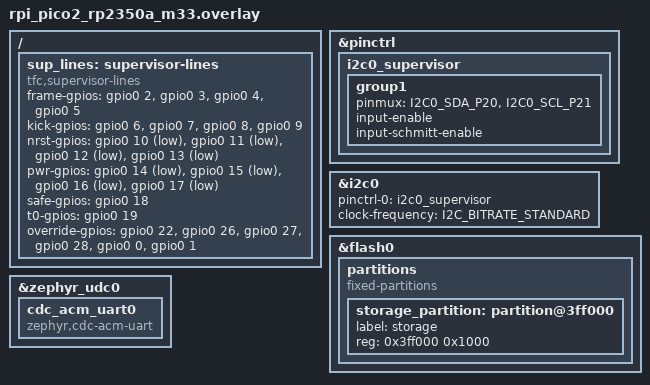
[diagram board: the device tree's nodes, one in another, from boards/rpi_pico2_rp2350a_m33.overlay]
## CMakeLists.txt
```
cmake_minimum_required(VERSION 3.20.0)
find_package(Zephyr REQUIRED HINTS $ENV{ZEPHYR_BASE})
project(tfc_supervisor LANGUAGES C CXX)

# The supervisor shares no code with core/ (TFC-SUP-001): only its own logic, supervisor/include.
target_include_directories(app PRIVATE ${CMAKE_CURRENT_LIST_DIR}/../../supervisor/include)
target_sources(app PRIVATE src/main.cpp src/usb_init.c)
```

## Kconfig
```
# SPDX-License-Identifier: MIT
mainmenu "Supervisor (Pico 2, SUP-Lite)"

config TFC_USB_VID
	hex "USB vendor id"
	default 0x1209
	help
	  The pid.codes open vendor id, for a private bench device. Nothing here is for sale or for the field.

config TFC_USB_PID
	hex "USB product id"
	default 0x0002

config TFC_WATCHDOG_TIMEOUT_MS
	int "Hardware watchdog timeout (milliseconds)"
	default 100
	range 20 4000
	help
	  A supervisor that hangs resets itself and comes back with every output at its default and a warm start (it adopts running units and touches nothing).

config TFC_OVERRIDE_LINES_FITTED
	hex "Which hardware-override sense lines are wired (bit 0 H1 E-stop .. bit 5 H6/H7 node power-kill)"
	default 0x0
	range 0 0x3F
	help
	  The overrides' parts are ordered separately (docs/design/HARDWARE_OVERRIDE.md section 8). A line that is not wired is ignored; with none wired the feature is inert. A wired line that is engaged
	  blocks `launch` and `t0` until the operator types `override-ok`; the sense lines never change what the supervisor does to a unit (TFC-HWO-005).

source "Kconfig.zephyr"
```

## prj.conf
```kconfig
CONFIG_CPP=y
CONFIG_STD_CPP17=y
# Flight-code rules (ARCHITECTURE.md section 6): no exceptions, no RTTI, no heap.
CONFIG_CPP_EXCEPTIONS=n
CONFIG_CPP_RTTI=n
CONFIG_REQUIRES_FULL_LIBCPP=y
CONFIG_COMMON_LIBC_MALLOC=n

# The USB serial link to the PC (hardware commands in, status and events out)
CONFIG_USB_DEVICE_STACK_NEXT=y
CONFIG_USBD_CDC_ACM_CLASS=y
CONFIG_SERIAL=y
CONFIG_UART_LINE_CTRL=y
CONFIG_CDC_ACM_SERIAL_INITIALIZE_AT_BOOT=n

# The lines to the nodes, the real-time clock on I2C, the record of T-zero in flash, the watchdog
CONFIG_GPIO=y
CONFIG_I2C=y
CONFIG_FLASH=y
CONFIG_FLASH_MAP=y
CONFIG_WATCHDOG=y
CONFIG_HWINFO=y

CONFIG_LOG=y
CONFIG_USBD_LOG_LEVEL_ERR=y
CONFIG_UDC_DRIVER_LOG_LEVEL_ERR=y
CONFIG_USBD_CDC_ACM_LOG_LEVEL_OFF=y
CONFIG_MAIN_STACK_SIZE=4096
```

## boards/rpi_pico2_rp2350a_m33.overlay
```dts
/* The supervisor on a Pico 2 (docs/design/SUPERVISOR.md section 4, SUP-Lite; ADR-022).
 *
 * Pins (GP numbers): FRAME in GP2 to GP5 (A, B, C, ACT), KICK in GP6 to GP9, NRST out GP10 to GP13, power relay out GP14 to GP17 (active low, external pull-ups to 3.3 V), SAFE out GP18, T0 out GP19,
 * I2C0 to the real-time clock on GP20 (SDA) and GP21 (SCL), the six override sense inputs on GP22, GP26, GP27, GP28, GP0 and GP1 (H1 to H5 and H6/H7). All 26 pins. Every input needs an external pull-down of 8.2 kOhm or less (the RP2350 E9 erratum); the unit boards' own
 * outputs are push-pull. The NRST pins are driven open-drain by the program (an output pulled low to reset, an input otherwise), because the RP2350's GPIO has no open-drain mode.
 * The record of T-zero is kept in the last 4 KB sector of the 4 MB flash.
 */
#include <zephyr/dt-bindings/gpio/gpio.h>
#include <zephyr/dt-bindings/i2c/i2c.h>
#include <zephyr/dt-bindings/pinctrl/rpi-pico-rp2350a-pinctrl.h>

&pinctrl {
	i2c0_supervisor: i2c0_supervisor {
		group1 {
			pinmux = <I2C0_SDA_P20>, <I2C0_SCL_P21>;
			input-enable;
			input-schmitt-enable;
		};
	};
};

&i2c0 {
	pinctrl-0 = <&i2c0_supervisor>;
	pinctrl-names = "default";
	clock-frequency = <I2C_BITRATE_STANDARD>;
	status = "okay";
};

&flash0 {
	partitions {
		compatible = "fixed-partitions";
		#address-cells = <1>;
		#size-cells = <1>;

		storage_partition: partition@3ff000 {
			label = "storage";
			reg = <0x3ff000 0x1000>;
		};
	};
};

/ {
	sup_lines: supervisor-lines {
		compatible = "tfc,supervisor-lines";
		frame-gpios = <&gpio0 2 GPIO_ACTIVE_HIGH>, <&gpio0 3 GPIO_ACTIVE_HIGH>, <&gpio0 4 GPIO_ACTIVE_HIGH>, <&gpio0 5 GPIO_ACTIVE_HIGH>;
		kick-gpios = <&gpio0 6 GPIO_ACTIVE_HIGH>, <&gpio0 7 GPIO_ACTIVE_HIGH>, <&gpio0 8 GPIO_ACTIVE_HIGH>, <&gpio0 9 GPIO_ACTIVE_HIGH>;
		nrst-gpios = <&gpio0 10 GPIO_ACTIVE_LOW>, <&gpio0 11 GPIO_ACTIVE_LOW>, <&gpio0 12 GPIO_ACTIVE_LOW>, <&gpio0 13 GPIO_ACTIVE_LOW>;
		pwr-gpios = <&gpio0 14 GPIO_ACTIVE_LOW>, <&gpio0 15 GPIO_ACTIVE_LOW>, <&gpio0 16 GPIO_ACTIVE_LOW>, <&gpio0 17 GPIO_ACTIVE_LOW>;
		safe-gpios = <&gpio0 18 GPIO_ACTIVE_HIGH>;
		t0-gpios = <&gpio0 19 GPIO_ACTIVE_HIGH>;
		override-gpios = <&gpio0 22 GPIO_ACTIVE_HIGH>, <&gpio0 26 GPIO_ACTIVE_HIGH>, <&gpio0 27 GPIO_ACTIVE_HIGH>, <&gpio0 28 GPIO_ACTIVE_HIGH>, <&gpio0 0 GPIO_ACTIVE_HIGH>,
				  <&gpio0 1 GPIO_ACTIVE_HIGH>;
	};
};

/* The USB serial port to the PC: one CDC ACM function on the board's USB device controller. */
&zephyr_udc0 {
	cdc_acm_uart0 {
		compatible = "zephyr,cdc-acm-uart";
	};
};
```

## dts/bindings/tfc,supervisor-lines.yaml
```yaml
# SPDX-License-Identifier: MIT
description: The supervisor's lines to the three flight computers and the actuator node (A, B, C, ACT, in that order), and to ACT and the flight computers (SAFE, T0)
compatible: "tfc,supervisor-lines"
properties:
  frame-gpios:
    type: phandle-array
    required: true
    description: FRAME inputs, one per unit; a rising edge at the start of every frame. Each needs an external pull-down of 8.2 kOhm or less (RP2350 erratum E9)
  kick-gpios:
    type: phandle-array
    required: true
    description: KICK inputs, one per unit; a rising edge at the end of every completed frame (the watchdog line, TFC-FDIR-038)
  nrst-gpios:
    type: phandle-array
    required: true
    description: NRST outputs, one per unit, driven open-drain by hand (an output pulled low to reset, an input otherwise); active low
  pwr-gpios:
    type: phandle-array
    required: true
    description: Power relay inputs, one per unit; active low with external pull-ups so that a pin that is not driven means "powered"
  safe-gpios:
    type: phandle-array
    required: true
    description: SAFE output to ACT (high is Safe); default low
  t0-gpios:
    type: phandle-array
    required: true
    description: T0 output to every flight computer (a pulse at T-zero); default low
  override-gpios:
    type: phandle-array
    description: |
      The hardware overrides' read-only sense inputs (docs/design/HARDWARE_OVERRIDE.md, TFC-HWO-005), six of them in the order of supervisor/include/sup/overrides.hpp: H1 E-stop, H2 FORCE-SAFE, H3
      PLATFORM-LEVEL, H4 INJECTOR-DISARM, H5 SUPERVISOR-DISARM, H6/H7 any node power-kill. High means engaged. Each needs an external pull-down of 8.2 kOhm or less (RP2350 erratum E9).
      Optional; which of them exist is CONFIG_TFC_OVERRIDE_LINES_FITTED.
```

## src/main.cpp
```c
// SPDX-License-Identifier: MIT
// The supervisor on the Pico 2 (SUP-Lite, docs/design/SUPERVISOR.md; ADR-022). The board's side of sup::Supervisor (supervisor/include/sup/supervisor.hpp, tested on the host with a simulation of the
// units it watches). Every millisecond this loop
//   - reads the cumulative FRAME and KICK edge counts and the tick of the latest edge of each of the four units (the edges are counted in the GPIO interrupts),
//   - reads a command line if one has come in over USB serial (reset, cycle, hold, release, safe-now, safe-clear, launch, scrub, t0, override-ok, time, status),
//   - gives both to the logic and applies the levels it returns: NRST (driven open-drain by hand), the power relays (active low, external pull-ups), SAFE and T0,
//   - answers the command and reports what happened (a reset, a power-cycle, a unit declared DEAD, a period or phase out of limit, T-zero),
//   - feeds the hardware watchdog.
// At power-up every output is at its default before anything else can go wrong: no reset, no relay, SAFE and T0 low. The record of T-zero is kept in the last flash sector, so that after a
// reset or a power cut the mission clock is resumed from the battery-backed RTC (docs/design/MISSION_CLOCK.md). It shares no code with core/ (TFC-SUP-001). None of this has been run on a board.
//
// Include the C++ standard library BEFORE Zephyr headers: Zephyr defines an `__unused` macro that breaks a glibc header.
#include <array>
#include <cstdint>
#include <cstring>

#include "sup/rtc.hpp"
#include "sup/supervisor.hpp"

#include "usb_init.h"

#include <zephyr/device.h>
#include <zephyr/devicetree.h>
#include <zephyr/drivers/gpio.h>
#include <zephyr/drivers/i2c.h>
#include <zephyr/drivers/uart.h>
#include <zephyr/drivers/watchdog.h>
#include <zephyr/kernel.h>
#include <zephyr/storage/flash_map.h>
#include <zephyr/sys/util.h>
#include <zephyr/usb/usbd.h>

namespace {

constexpr unsigned kUnits = sup::kUnits;
const struct device* const g_uart = DEVICE_DT_GET_ONE(zephyr_cdc_acm_uart);
const struct device* const g_i2c = DEVICE_DT_GET(DT_NODELABEL(i2c0));
constexpr uint16_t kRtcAddress = 0x68;

#define LINE(prop, i) GPIO_DT_SPEC_GET_BY_IDX(DT_NODELABEL(sup_lines), prop, i)
const struct gpio_dt_spec g_frame[kUnits] = {LINE(frame_gpios, 0), LINE(frame_gpios, 1), LINE(frame_gpios, 2), LINE(frame_gpios, 3)};
const struct gpio_dt_spec g_kick[kUnits] = {LINE(kick_gpios, 0), LINE(kick_gpios, 1), LINE(kick_gpios, 2), LINE(kick_gpios, 3)};
const struct gpio_dt_spec g_nrst[kUnits] = {LINE(nrst_gpios, 0), LINE(nrst_gpios, 1), LINE(nrst_gpios, 2), LINE(nrst_gpios, 3)};
const struct gpio_dt_spec g_pwr[kUnits] = {LINE(pwr_gpios, 0), LINE(pwr_gpios, 1), LINE(pwr_gpios, 2), LINE(pwr_gpios, 3)};
const struct gpio_dt_spec g_safe = GPIO_DT_SPEC_GET(DT_NODELABEL(sup_lines), safe_gpios);
const struct gpio_dt_spec g_t0 = GPIO_DT_SPEC_GET(DT_NODELABEL(sup_lines), t0_gpios);
#if DT_NODE_HAS_PROP(DT_NODELABEL(sup_lines), override_gpios)
const struct gpio_dt_spec g_override[sup::kOverrideLines] = {LINE(override_gpios, 0), LINE(override_gpios, 1), LINE(override_gpios, 2),
                                                             LINE(override_gpios, 3), LINE(override_gpios, 4), LINE(override_gpios, 5)};
constexpr bool kHaveOverrideLines = true;
#else
constexpr bool kHaveOverrideLines = false;
#endif

// The edge counters, written in the GPIO interrupt and read with interrupts off.
struct Edges {
  uint32_t frames = 0U;
  uint64_t frame_tick = 0U;
  uint32_t kicks = 0U;
  uint64_t kick_tick = 0U;
};
Edges g_edges[kUnits];

struct EdgeCallback {
  struct gpio_callback cb;
  unsigned unit;
  bool kick;
};
EdgeCallback g_callbacks[2U * kUnits];

uint64_t now_ticks() { return k_cyc_to_us_floor64(k_cycle_get_64()); }  // 1 MHz, as sup::SupConfig::tick_hz

void on_edge(const struct device*, struct gpio_callback* cb, uint32_t) {
  EdgeCallback* e = CONTAINER_OF(cb, EdgeCallback, cb);
  const uint64_t t = now_ticks();
  if (e->kick) {
    ++g_edges[e->unit].kicks;
    g_edges[e->unit].kick_tick = t;
  } else {
    ++g_edges[e->unit].frames;
    g_edges[e->unit].frame_tick = t;
  }
}

bool watch(const struct gpio_dt_spec& pin, unsigned index, unsigned unit, bool kick) {
  if (!gpio_is_ready_dt(&pin) || gpio_pin_configure_dt(&pin, GPIO_INPUT) != 0) {
    return false;
  }
  EdgeCallback& e = g_callbacks[index];
  e.unit = unit;
  e.kick = kick;
  gpio_init_callback(&e.cb, on_edge, BIT(pin.pin));
  return gpio_add_callback(pin.port, &e.cb) == 0 && gpio_pin_interrupt_configure_dt(&pin, GPIO_INT_EDGE_RISING) == 0;
}

// NRST: an output pulled low to reset, an input (high impedance) otherwise.
void set_nrst(unsigned u, bool low) {
  static bool last[kUnits];
  static bool known[kUnits];
  if (known[u] && last[u] == low) {
    return;
  }
  known[u] = true;
  last[u] = low;
  if (low) {
    (void)gpio_pin_configure_dt(&g_nrst[u], GPIO_OUTPUT_ACTIVE);
  } else {
    (void)gpio_pin_configure_dt(&g_nrst[u], GPIO_INPUT);
  }
}

void apply(const sup::Outputs& o) {
  for (unsigned u = 0; u < kUnits; ++u) {
    set_nrst(u, o.nrst_low[u]);
    (void)gpio_pin_set_dt(&g_pwr[u], o.power_cut[u] ? 1 : 0);  // the devicetree says active low: logical 1 is the relay energised
  }
  (void)gpio_pin_set_dt(&g_safe, o.safe_line ? 1 : 0);
  (void)gpio_pin_set_dt(&g_t0, o.t0_line ? 1 : 0);
}

void say(const char* text) {
  const std::size_t n = std::strlen(text);
  std::size_t sent = 0U;
  for (int tries = 0; tries < 4 && sent < n; ++tries) {  // a short write is a lost line: the operator asks again
    sent += static_cast<std::size_t>(uart_fifo_fill(g_uart, reinterpret_cast<const uint8_t*>(text) + sent, static_cast<int>(n - sent)));
  }
}

// The real-time clock: seconds since 2000-01-01, or invalid.
sup::RtcReading read_rtc() {
  std::array<uint8_t, 7> r{};
  uint8_t reg = 0x00;
  uint8_t status = 0x80;
  if (!device_is_ready(g_i2c) || i2c_write_read(g_i2c, kRtcAddress, &reg, 1, r.data(), static_cast<uint32_t>(r.size())) != 0) {
    return sup::RtcReading{};
  }
  reg = 0x0F;
  if (i2c_write_read(g_i2c, kRtcAddress, &reg, 1, &status, 1) != 0) {
    return sup::RtcReading{};
  }
  return sup::ds3231_seconds(r, status);
}

// The record of T-zero in the last flash sector.
bool load_record(sup::MetRecord& rec) {
  const struct flash_area* fa = nullptr;
  if (flash_area_open(FIXED_PARTITION_ID(storage_partition), &fa) != 0) {
    return false;
  }
  const bool ok = flash_area_read(fa, 0, &rec, sizeof rec) == 0;
  flash_area_close(fa);
  return ok;
}

void store_record(const sup::MetRecord& rec) {
  const struct flash_area* fa = nullptr;
  if (flash_area_open(FIXED_PARTITION_ID(storage_partition), &fa) != 0) {
    return;
  }
  if (flash_area_erase(fa, 0, 4096U) == 0) {
    (void)flash_area_write(fa, 0, &rec, sizeof rec);
  }
  flash_area_close(fa);
}

void usb_message(struct usbd_context* const ctx, const struct usbd_msg* msg) {
  if (usbd_can_detect_vbus(ctx)) {
    if (msg->type == USBD_MSG_VBUS_READY) {
      (void)usbd_enable(ctx);
    } else if (msg->type == USBD_MSG_VBUS_REMOVED) {
      (void)usbd_disable(ctx);
    }
  }
}

const char* const kUnitNames[kUnits] = {"A", "B", "C", "ACT"};

}  // namespace

int main() {
  // Every output at its default first: no relay energised, NRST released, SAFE and T0 low (TFC-SUP-007).
  for (unsigned u = 0; u < kUnits; ++u) {
    if (gpio_is_ready_dt(&g_pwr[u])) {
      (void)gpio_pin_configure_dt(&g_pwr[u], GPIO_OUTPUT_INACTIVE);
    }
    if (gpio_is_ready_dt(&g_nrst[u])) {
      (void)gpio_pin_configure_dt(&g_nrst[u], GPIO_INPUT);
    }
  }
  if (gpio_is_ready_dt(&g_safe)) {
    (void)gpio_pin_configure_dt(&g_safe, GPIO_OUTPUT_INACTIVE);
  }
  if (gpio_is_ready_dt(&g_t0)) {
    (void)gpio_pin_configure_dt(&g_t0, GPIO_OUTPUT_INACTIVE);
  }
  struct usbd_context* usb = tfc_usbd_init(usb_message);
  if (usb != nullptr && !usbd_can_detect_vbus(usb)) {
    (void)usbd_enable(usb);
  }
  bool lines_ok = device_is_ready(g_uart);
  for (unsigned u = 0; u < kUnits; ++u) {
    lines_ok = watch(g_frame[u], 2U * u, u, false) && watch(g_kick[u], (2U * u) + 1U, u, true) && lines_ok;
  }
  if (!lines_ok) {
    return 1;
  }

  const struct device* const wdt = DEVICE_DT_GET(DT_ALIAS(watchdog0));
  int wdt_channel = -1;
  if (device_is_ready(wdt)) {
    wdt_timeout_cfg wcfg{};
    wcfg.flags = WDT_FLAG_RESET_SOC;
    wcfg.window.min = 0U;
    wcfg.window.max = CONFIG_TFC_WATCHDOG_TIMEOUT_MS;
    wdt_channel = wdt_install_timeout(wdt, &wcfg);
    if (wdt_channel >= 0 && wdt_setup(wdt, WDT_OPT_PAUSE_HALTED_BY_DBG) != 0) {
      wdt_channel = -1;
    }
  }

  sup::SupConfig sup_cfg;
  sup_cfg.override_fitted = kHaveOverrideLines ? static_cast<uint8_t>(CONFIG_TFC_OVERRIDE_LINES_FITTED) : 0U;
#if DT_NODE_HAS_PROP(DT_NODELABEL(sup_lines), override_gpios)
  for (unsigned i = 0; i < sup::kOverrideLines; ++i) {
    if (((sup_cfg.override_fitted >> i) & 1U) != 0U && gpio_is_ready_dt(&g_override[i])) {
      (void)gpio_pin_configure_dt(&g_override[i], GPIO_INPUT);
    }
  }
#endif
  sup::Supervisor supervisor(sup_cfg);
  if (!supervisor.config_ok()) {  // a clock that cannot make a whole frame of ticks: it does not act (every node keeps running, TFC-SUP-007) and says why
    say("supervisor: the clock configuration is invalid; it will not act\n");
    for (;;) {
      k_sleep(K_FOREVER);
    }
  }
  sup::RtcReading rtc = read_rtc();
  {
    sup::MetRecord rec;
    if (rtc.valid && load_record(rec) && supervisor.restore(rec, now_ticks(), rtc.seconds)) {
      say("T-zero record found: the mission clock is resumed from the RTC (good to a second)\n");
    }
  }
  say("supervisor up\n");

  std::array<char, 48> line{};
  std::size_t line_len = 0U;
  uint64_t next_rtc = now_ticks() + 1000000U;
  int64_t next = k_uptime_get() + 1;
  for (;;) {
    sup::Inputs in;
    const unsigned key = irq_lock();
    for (unsigned u = 0; u < kUnits; ++u) {
      in.unit[u].frames = g_edges[u].frames;
      in.unit[u].frame_tick = g_edges[u].frame_tick;
      in.unit[u].kicks = g_edges[u].kicks;
      in.unit[u].kick_tick = g_edges[u].kick_tick;
    }
    irq_unlock(key);
    in.ticks = now_ticks();
    if (in.ticks >= next_rtc) {  // the RTC once a second
      next_rtc = in.ticks + 1000000U;
      rtc = read_rtc();
    }
    in.rtc_s = rtc.valid ? rtc.seconds : 0U;
#if DT_NODE_HAS_PROP(DT_NODELABEL(sup_lines), override_gpios)
    for (unsigned i = 0; i < sup::kOverrideLines; ++i) {  // the override sense lines: read-only (TFC-HWO-005)
      if (((sup_cfg.override_fitted >> i) & 1U) != 0U && gpio_pin_get_dt(&g_override[i]) > 0) {
        in.overrides = static_cast<uint8_t>(in.overrides | (1U << i));
      }
    }
#endif

    sup::Command cmd;
    bool have_cmd = false;
    uint8_t ch = 0U;
    for (unsigned i = 0; i < 16U && !have_cmd && uart_poll_in(g_uart, &ch) == 0; ++i) {  // at most 16 characters per millisecond
      if (ch == '\n' || ch == '\r') {
        if (line_len > 0U) {
          cmd = sup::parse_command(line.data(), line_len);
          have_cmd = true;
          line_len = 0U;
        }
      } else if (line_len < line.size()) {
        line[line_len++] = static_cast<char>(ch);
      } else {
        line_len = line.size() + 1U;  // too long: parse_command will refuse it when the line ends
      }
    }
    if (line_len > line.size()) {
      line_len = 0U;
      cmd = sup::Command{};
      cmd.parse = sup::Parse::TooLong;
      have_cmd = true;
    }

    sup::Events ev;
    sup::Response resp = sup::Response::Done;
    const sup::Outputs out = supervisor.step(in, have_cmd ? &cmd : nullptr, ev, resp);
    apply(out);

    if (have_cmd) {
      if (resp == sup::Response::Done && cmd.kind == sup::Kind::Time) {
        std::array<char, 96> text{};
        (void)supervisor.time_text(in, text.data(), text.size());
        say(text.data());
      } else if (resp == sup::Response::Done && cmd.kind == sup::Kind::Status) {
        std::array<char, 400> text{};
        (void)supervisor.status_text(text.data(), text.size());
        say(text.data());
      } else {
        say(resp == sup::Response::Done ? "ok\n" : (resp == sup::Response::Refused ? "refused\n" : "unknown command\n"));
      }
    }
    for (unsigned u = 0; u < kUnits; ++u) {
      std::array<char, 64> msg{};
      if (ev.reset[u]) {
        (void)snprintk(msg.data(), msg.size(), "RESET %s (kicks stopped)\n", kUnitNames[u]);
        say(msg.data());
      }
      if (ev.cycle[u]) {
        (void)snprintk(msg.data(), msg.size(), "POWER-CYCLE %s\n", kUnitNames[u]);
        say(msg.data());
      }
      if (ev.dead[u]) {
        (void)snprintk(msg.data(), msg.size(), "DEAD %s: held in reset; `release %s` to try again\n", kUnitNames[u], kUnitNames[u]);
        say(msg.data());
      }
      if (ev.period_bad[u]) {
        (void)snprintk(msg.data(), msg.size(), "PERIOD %s out of limit (%d ppm)\n", kUnitNames[u], static_cast<int>(supervisor.period_ppm(static_cast<sup::Unit>(u))));
        say(msg.data());
      }
      if (ev.mission_bad[u]) {
        (void)snprintk(msg.data(), msg.size(), "MISSION TIME %s disagrees with the clock\n", kUnitNames[u]);
        say(msg.data());
      }
    }
    std::array<char, 96> omsg{};
    if (ev.overrides_changed != 0U) {
      (void)snprintk(omsg.data(), omsg.size(), "OVERRIDE lines changed 0x%02x: engaged now 0x%02x\n", static_cast<unsigned>(ev.overrides_changed),
                     static_cast<unsigned>(supervisor.overrides_engaged()));
      say(omsg.data());
    }
    if (ev.launch_blocked != 0U) {
      (void)snprintk(omsg.data(), omsg.size(), "LAUNCH REFUSED: override 0x%02x is engaged; `override-ok` accepts it\n", static_cast<unsigned>(ev.launch_blocked));
      say(omsg.data());
    }
    if (ev.launch_untested != 0U) {
      (void)snprintk(omsg.data(), omsg.size(), "overrides not yet tested this session: 0x%02x\n", static_cast<unsigned>(ev.launch_untested));
      say(omsg.data());
    }
    if (ev.warm_start) {
      say("warm start: units are running, nothing is touched\n");
    }
    if (ev.cold_start) {
      say("cold start: every unit held in reset, released in order ACT, A, B, C\n");
    }
    if (ev.phase_bad) {
      say("PHASE: two flight computers' frame starts are more than 200 us apart\n");
    }
    if (ev.total_loss) {
      say("TOTAL LOSS: no flight computer is kicking\n");
    }
    if (ev.countdown_started) {
      say("countdown: T-10 s\n");
    }
    if (ev.scrubbed) {
      say("countdown scrubbed\n");
    }
    if (ev.t0) {
      say("T-ZERO\n");
      store_record(ev.record);
    }

    if (wdt_channel >= 0) {
      (void)wdt_feed(wdt, wdt_channel);
    }
    const int64_t now = k_uptime_get();
    if (next > now) {
      k_msleep(static_cast<int32_t>(next - now));
    }
    ++next;
  }
}
```

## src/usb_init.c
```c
/* SPDX-License-Identifier: MIT
 *
 * The USB device description for the Pico: one CDC ACM serial port. Written against Zephyr's documented USB device (next) API; Zephyr's own sample helper is
 * not used because its options are limited to the samples in Zephyr's tree.
 */
#include "usb_init.h"

#include <zephyr/device.h>
#include <zephyr/kernel.h>
#include <zephyr/logging/log.h>
#include <zephyr/usb/usbd.h>

LOG_MODULE_REGISTER(tfc_usb, LOG_LEVEL_ERR);

USBD_DEVICE_DEFINE(tfc_usbd, DEVICE_DT_GET(DT_NODELABEL(zephyr_udc0)), CONFIG_TFC_USB_VID, CONFIG_TFC_USB_PID);

USBD_DESC_LANG_DEFINE(tfc_lang);
USBD_DESC_MANUFACTURER_DEFINE(tfc_mfr, "Triplex FC bench");
USBD_DESC_PRODUCT_DEFINE(tfc_product, "Supervisor");
USBD_DESC_SERIAL_NUMBER_DEFINE(tfc_sn);

USBD_DESC_CONFIG_DEFINE(tfc_fs_cfg_desc, "FS Configuration");
USBD_CONFIGURATION_DEFINE(tfc_fs_config, 0 /* bus powered, no remote wakeup */, 50 /* 100 mA, in 2 mA units */, &tfc_fs_cfg_desc);

struct usbd_context *tfc_usbd_init(usbd_msg_cb_t msg_cb)
{
	if (usbd_add_descriptor(&tfc_usbd, &tfc_lang) || usbd_add_descriptor(&tfc_usbd, &tfc_mfr) || usbd_add_descriptor(&tfc_usbd, &tfc_product) ||
	    usbd_add_descriptor(&tfc_usbd, &tfc_sn)) {
		LOG_ERR("cannot add the string descriptors");
		return NULL;
	}
	if (usbd_add_configuration(&tfc_usbd, USBD_SPEED_FS, &tfc_fs_config)) {
		LOG_ERR("cannot add the configuration");
		return NULL;
	}
	if (usbd_register_all_classes(&tfc_usbd, USBD_SPEED_FS, 1, NULL)) {
		LOG_ERR("cannot register the classes");
		return NULL;
	}
	/* a class with more than one interface uses an Interface Association Descriptor: miscellaneous device, common class */
	usbd_device_set_code_triple(&tfc_usbd, USBD_SPEED_FS, USB_BCC_MISCELLANEOUS, 0x02, 0x01);
	usbd_self_powered(&tfc_usbd, false);
	if (msg_cb != NULL && usbd_msg_register_cb(&tfc_usbd, msg_cb)) {
		LOG_ERR("cannot register the message callback");
		return NULL;
	}
	if (usbd_init(&tfc_usbd)) {
		LOG_ERR("cannot initialise the USB device");
		return NULL;
	}
	return &tfc_usbd;
}
```

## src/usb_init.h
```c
/* SPDX-License-Identifier: MIT */
#ifndef TFC_SUP_USB_INIT_H
#define TFC_SUP_USB_INIT_H

#include <zephyr/usb/usbd.h>

#ifdef __cplusplus
extern "C" {
#endif

/* Describe the device (one CDC ACM serial port, full speed, bus powered), register `msg_cb`, and initialise the USB device stack. Call usbd_enable() on the result
 * (or wait for VBUS if usbd_can_detect_vbus()). NULL if anything failed. */
struct usbd_context *tfc_usbd_init(usbd_msg_cb_t msg_cb);

#ifdef __cplusplus
}
#endif

#endif
```
